# GD32F5HC register map
File version: 1.0
CPU: CM33 r0p4, little endian, MPU, FPU, 4 interrupt priority bits
Registers are 32-bit, read-write, reset 0x0 unless marked. A register's access mark holds for its fields unless they carry their own. Offsets are from the block's base; [hi:lo] are bit positions.

## USART0 — Universal synchronous asynchronous receiver transmitter
Base 0x40004800
Same registers: USART2 0x40011000, SEC_USART0 0x50004800, SEC_USART2 0x50011000
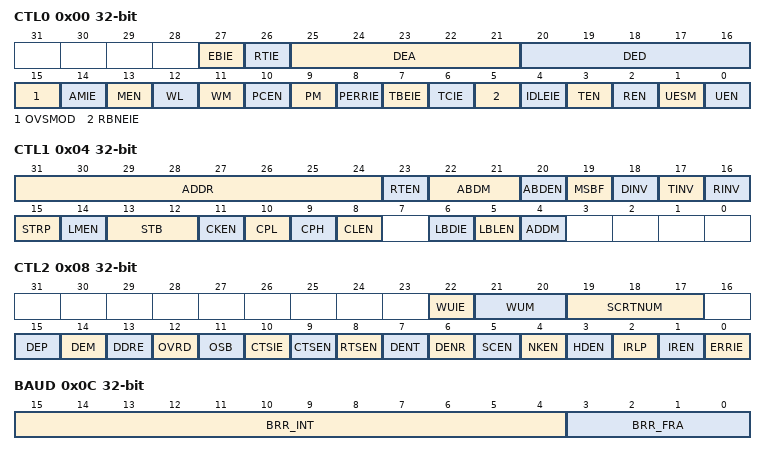
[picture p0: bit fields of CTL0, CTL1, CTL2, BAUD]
0x00 CTL0 — Control register 0
  [27] EBIE — End of Block interrupt enable
  [26] RTIE — Receiver timeout interrupt enable
  [25:21] DEA — Driver Enable assertion time
  [20:16] DED — Driver Enable deassertion time
  [15] OVSMOD — Oversampling mode
  [14] AMIE — Character match interrupt enable
  [13] MEN — Mute mode enable
  [12] WL — Word length
  [11] WM — Receiver wakeup method
  [10] PCEN — Parity control enable
  [9] PM — Parity selection
  [8] PERRIE — PE interrupt enable
  [7] TBEIE — interrupt enable
  [6] TCIE — Transmission complete interrupt enable
  [5] RBNEIE — RXNE interrupt enable
  [4] IDLEIE — IDLE interrupt enable
  [3] TEN — Transmitter enable
  [2] REN — Receiver enable
  [1] UESM — USART enable in Stop mode
  [0] UEN — USART enable
0x04 CTL1 — Control register 1
  [31:24] ADDR — Address of the USART terminal
  [23] RTEN — Receiver timeout enable
  [22:21] ABDM — Auto baud rate mode
  [20] ABDEN — Auto baud rate enable
  [19] MSBF — Most significant bit first
  [18] DINV — Data bit level inversion
  [17] TINV — TX pin active level inversion
  [16] RINV — RX pin active level inversion
  [15] STRP — Swap TX/RX pins
  [14] LMEN — LIN mode enable
  [13:12] STB — STOP bits
  [11] CKEN — Clock enable
  [10] CPL — Clock polarity
  [9] CPH — Clock phase
  [8] CLEN — Last bit clock pulse
  [6] LBDIE — LIN break detection interrupt enable
  [5] LBLEN — LIN break detection length
  [4] ADDM — 7-bit Address Detection/4-bit Address Detection
0x08 CTL2 — Control register 2
  [22] WUIE — Wakeup from Stop mode interrupt enable
  [21:20] WUM — Wakeup from Stop mode interrupt flag selection
  [19:17] SCRTNUM — Smartcard auto-retry count
  [15] DEP — Driver enable polarity selection
  [14] DEM — Driver enable mode
  [13] DDRE — DMA Disable on Reception Error
  [12] OVRD — Overrun Disable
  [11] OSB — One sample bit method enable
  [10] CTSIE — CTS interrupt enable
  [9] CTSEN — CTS enable
  [8] RTSEN — RTS enable
  [7] DENT — DMA enable transmitter
  [6] DENR — DMA enable receiver
  [5] SCEN — Smartcard mode enable
  [4] NKEN — Smartcard NACK enable
  [3] HDEN — Half-duplex selection
  [2] IRLP — IrDA low-power
  [1] IREN — IrDA mode enable
  [0] ERRIE — Error interrupt enable
0x0C BAUD — Baud rate register
  [15:4] BRR_INT — integer of baud-rate divider
  [3:0] BRR_FRA — integer of baud-rate divider
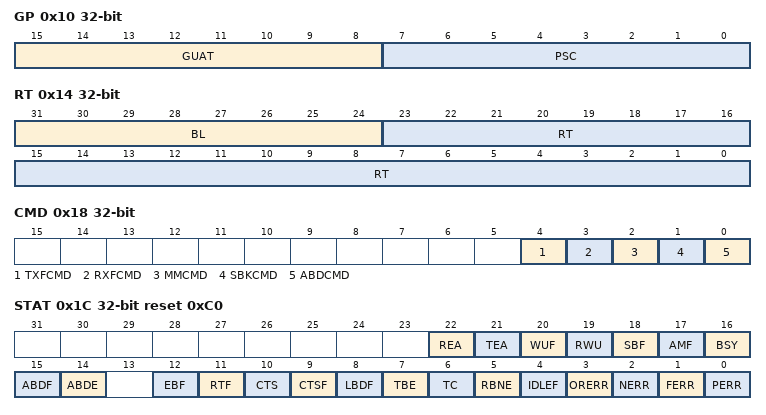
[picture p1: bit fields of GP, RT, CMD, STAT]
0x10 GP — Guard time and prescaler register
  [15:8] GUAT — Guard time value
  [7:0] PSC — Prescaler value
0x14 RT — Receiver timeout register
  [31:24] BL — Block Length
  [23:0] RT — Receiver timeout value
0x18 CMD wo — Command register
  [4] TXFCMD — Transmit data flush request
  [3] RXFCMD — Receive data flush request
  [2] MMCMD — Mute mode request
  [1] SBKCMD — Send break request
  [0] ABDCMD — Auto baudrate detection request
0x1C STAT ro reset 0xC0 — Interrupt & status register
  [22] REA — Receive enable acknowledge flag
  [21] TEA — Transmit enable acknowledge flag
  [20] WUF — Wakeup from Stop mode flag
  [19] RWU — Receiver wakeup from Mute mode
  [18] SBF — Send break flag
  [17] AMF — character match flag
  [16] BSY — Busy flag
  [15] ABDF — Auto baudrate detection flag
  [14] ABDE — Auto baudrate detection error
  [12] EBF — End of block flag
  [11] RTF — Receiver timeout
  [10] CTS — CTS flag
  [9] CTSF — CTS interrupt flag
  [8] LBDF — LIN break detection flag
  [7] TBE — Transmit data register empty
  [6] TC — Transmission complete
  [5] RBNE — Read data register not empty
  [4] IDLEF — Idle line detected
  [3] ORERR — Overrun error
  [2] NERR — Noise detected flag
  [1] FERR — Framing error
  [0] PERR — Parity error
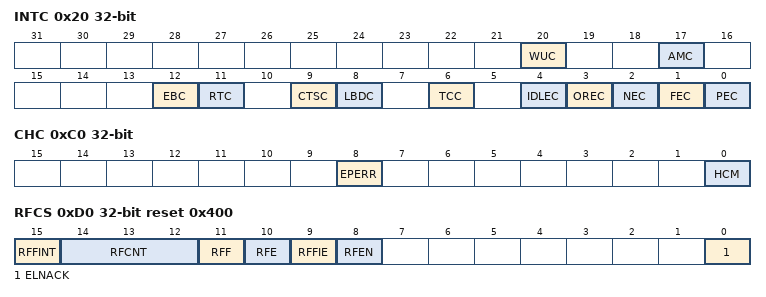
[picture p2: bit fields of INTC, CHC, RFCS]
0x20 INTC wo — Interrupt flag clear register
  [20] WUC — Wakeup from Stop mode clear flag
  [17] AMC — Character match clear flag
  [12] EBC — End of timeout clear flag
  [11] RTC — Receiver timeout clear flag
  [9] CTSC — CTS clear flag
  [8] LBDC — LIN break detection clear flag
  [6] TCC — Transmission complete clear flag
  [4] IDLEC — Idle line detected clear flag
  [3] OREC — Overrun error clear flag
  [2] NEC — Noise detected clear flag
  [1] FEC — Frame error clear flag
  [0] PEC — Parity error clear flag
0x24 RDATA ro — Receive data register
  [8:0] RDATA — Receive data value
0x28 TDATA — Transmit data register
  [8:0] TDATA — Transmit data value
0xC0 CHC — coherence control register
  [8] EPERR — Early parity error flag
  [0] HCM — Hardware flow control coherence mode
0xD0 RFCS access per field reset 0x400 — USART receive FIFO control and status register
  [15] RFFINT rw — Receive FIFO full interrupt flag
  [14:12] RFCNT ro — Receive FIFO count number
  [11] RFF ro — Receive FIFO full flag
  [10] RFE ro — Receive FIFO empty flag
  [9] RFFIE rw — Receive FIFO full interrupt enable
  [8] RFEN rw — Receive FIFO enable
  [0] ELNACK rw — Early NKEN when smartcard mode is selected
